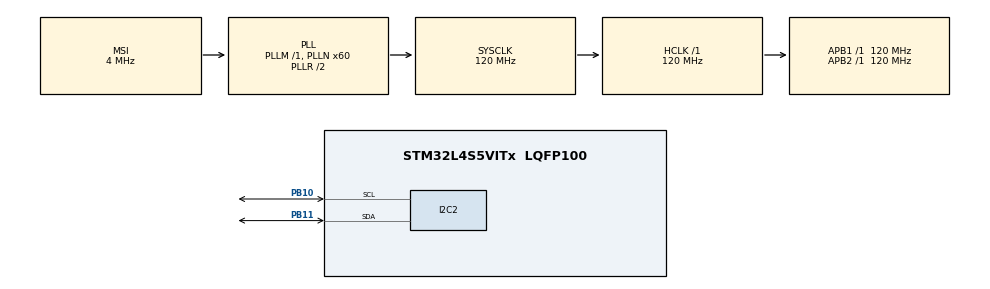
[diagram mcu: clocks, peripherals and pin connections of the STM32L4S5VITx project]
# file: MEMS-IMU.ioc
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I2C2.Timing=0x30A175AB
Mcu.Family=STM32L4
Mcu.Name=STM32L4S5VITx
Mcu.Package=LQFP100
NVIC.PriorityGroup=NVIC_PRIORITYGROUP_4
PB10.Mode=I2C
PB10.Signal=I2C2_SCL
PB11.Mode=I2C
PB11.Signal=I2C2_SDA
ProjectManager.HeapSize=0x200
ProjectManager.StackSize=0x400
ProjectManager.TargetToolchain=STM32CubeIDE
RCC.ADCFreq_Value=48000000
RCC.AHBFreq_Value=120000000
RCC.APB1Freq_Value=120000000
RCC.APB1TimFreq_Value=120000000
RCC.APB2Freq_Value=120000000
RCC.APB2TimFreq_Value=120000000
RCC.CortexFreq_Value=120000000
RCC.HCLKFreq_Value=120000000
RCC.HSE_VALUE=8000000
RCC.HSI48_VALUE=48000000
RCC.HSI_VALUE=16000000
RCC.MSI_VALUE=4000000
RCC.PLLN=60
RCC.PLLSAI1N=24
RCC.SYSCLKFreq_VALUE=120000000
RCC.SYSCLKSource=RCC_SYSCLKSOURCE_PLLCLK
RCC.USBFreq_Value=48000000
RCC.VCOOutputFreq_Value=240000000
board=B-L4S5I-IOT01A

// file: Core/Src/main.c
/* USER CODE BEGIN Header */
/**
  ******************************************************************************
  * @file           : main.c
  * @brief          : Main program body
  ******************************************************************************
  * @attention
  *
  * Copyright (c) 2026 STMicroelectronics.
  * All rights reserved.
  *
  * This software is licensed under terms that can be found in the LICENSE file
  * in the root directory of this software component.
  * If no LICENSE file comes with this software, it is provided AS-IS.
  *
  ******************************************************************************
  */
/* USER CODE END Header */
#include "main.h"

/* USER CODE BEGIN Includes */
#include "LSM6DSL.h"
#include <stdint.h>

HAL_StatusTypeDef status;

int16_t raw_x;
int16_t raw_y;
int16_t raw_z;

float ax_mg;
float ay_mg;
float az_mg;

float ax_g;
float ay_g;
float az_g;

float ax_ms2;
float ay_ms2;
float az_ms2;

int16_t gx, gy, gz;

float gx_dps;
float gy_dps;
float gz_dps;

/* USER CODE END Includes */

I2C_HandleTypeDef hi2c2;

void SystemClock_Config(void);
static void MX_GPIO_Init(void);
static void MX_I2C2_Init(void);
/* USER CODE BEGIN PFP */
int __io_putchar(int ch)
{
    ITM_SendChar(ch);
    return ch;
}
/* USER CODE END PFP */

int main(void)
{

  /* MCU Configuration--------------------------------------------------------*/

  /* Reset of all peripherals, Initializes the Flash interface and the Systick. */
  HAL_Init();

  /* Configure the system clock */
  SystemClock_Config();

  /* Initialize all configured peripherals */
  MX_GPIO_Init();
  MX_I2C2_Init();
  /* USER CODE BEGIN 2 */

  if (LSM6DSL_Init() != HAL_OK)
  {
      printf("LSM6DSL initialization FAILED\r\n");

      while (1)
      {
      }
  }

  printf("LSM6DSL initialization OK\r\n");

  /* USER CODE END 2 */

  /* Infinite loop */
  while (1)
  {

    /* USER CODE BEGIN 3 */
	  if (LSM6DSL_ReadAccel(&raw_x,
	                            &raw_y,
	                            &raw_z) == HAL_OK)
	      {
	          /*
	           * ±2 g sensitivity
	           *
	           * 0.061 mg/LSB
	           */

	          ax_mg = raw_x * 0.061f;
	          ay_mg = raw_y * 0.061f;
	          az_mg = raw_z * 0.061f;

	          /* Convert mg → g */

	          ax_g = ax_mg / 1000.0f;
	          ay_g = ay_mg / 1000.0f;
	          az_g = az_mg / 1000.0f;

	          /* Convert g → m/s² */

	          ax_ms2 = ax_g * 9.80665f;
	          ay_ms2 = ay_g * 9.80665f;
	          az_ms2 = az_g * 9.80665f;

	          printf("\r\n");

	          printf("RAW: ");
	          printf("X=%d  ", raw_x);
	          printf("Y=%d  ", raw_y);
	          printf("Z=%d\r\n", raw_z);

	          printf("ACC: ");
	          printf("X=%.3f mg  ", ax_mg);
	          printf("Y=%.3f mg  ", ay_mg);
	          printf("Z=%.3f mg\r\n", az_mg);

	          printf("ACC: ");
	          printf("X=%.3f g  ", ax_g);
	          printf("Y=%.3f g  ", ay_g);
	          printf("Z=%.3f g\r\n", az_g);

	          printf("ACC: ");
	          printf("X=%.3f m/s2  ", ax_ms2);
	          printf("Y=%.3f m/s2  ", ay_ms2);
	          printf("Z=%.3f m/s2\r\n", az_ms2);
	      }
	      else
	      {
	          printf("Accelerometer read error\r\n");
	      }

	      if(LSM6DSL_ReadGyro(&gx, &gy, &gz) == HAL_OK){

	      /* ±245 dps → 8.75 mdps/LSB = 0.00875 dps/LSB */

	      gx_dps = gx * 0.00875f;
	      gy_dps = gy * 0.00875f;
	      gz_dps = gz * 0.00875f;

	      printf("GX: %.2f dps | GY: %.2f dps | GZ: %.2f dps\r\n",
	             gx_dps,
	             gy_dps,
	             gz_dps);

	      }
	      else{
	          printf("Gyroscope read error\r\n");

	      }

	      HAL_Delay(100);

  }
  /* USER CODE END 3 */
}

void SystemClock_Config(void)
{
  RCC_OscInitTypeDef RCC_OscInitStruct = {0};
  RCC_ClkInitTypeDef RCC_ClkInitStruct = {0};

  /** Configure the main internal regulator output voltage
  */
  if (HAL_PWREx_ControlVoltageScaling(PWR_REGULATOR_VOLTAGE_SCALE1_BOOST) != HAL_OK)
  {
    Error_Handler();
  }

  /** Initializes the RCC Oscillators according to the specified parameters
  * in the RCC_OscInitTypeDef structure.
  */
  RCC_OscInitStruct.OscillatorType = RCC_OSCILLATORTYPE_MSI;
  RCC_OscInitStruct.MSIState = RCC_MSI_ON;
  RCC_OscInitStruct.MSICalibrationValue = 0;
  RCC_OscInitStruct.MSIClockRange = RCC_MSIRANGE_6;
  RCC_OscInitStruct.PLL.PLLState = RCC_PLL_ON;
  RCC_OscInitStruct.PLL.PLLSource = RCC_PLLSOURCE_MSI;
  RCC_OscInitStruct.PLL.PLLM = 1;
  RCC_OscInitStruct.PLL.PLLN = 60;
  RCC_OscInitStruct.PLL.PLLP = RCC_PLLP_DIV2;
  RCC_OscInitStruct.PLL.PLLQ = RCC_PLLQ_DIV2;
  RCC_OscInitStruct.PLL.PLLR = RCC_PLLR_DIV2;
  if (HAL_RCC_OscConfig(&RCC_OscInitStruct) != HAL_OK)
  {
    Error_Handler();
  }

  /** Initializes the CPU, AHB and APB buses clocks
  */
  RCC_ClkInitStruct.ClockType = RCC_CLOCKTYPE_HCLK|RCC_CLOCKTYPE_SYSCLK
                              |RCC_CLOCKTYPE_PCLK1|RCC_CLOCKTYPE_PCLK2;
  RCC_ClkInitStruct.SYSCLKSource = RCC_SYSCLKSOURCE_PLLCLK;
  RCC_ClkInitStruct.AHBCLKDivider = RCC_SYSCLK_DIV1;
  RCC_ClkInitStruct.APB1CLKDivider = RCC_HCLK_DIV1;
  RCC_ClkInitStruct.APB2CLKDivider = RCC_HCLK_DIV1;

  if (HAL_RCC_ClockConfig(&RCC_ClkInitStruct, FLASH_LATENCY_5) != HAL_OK)
  {
    Error_Handler();
  }
}

static void MX_I2C2_Init(void)
{

  hi2c2.Instance = I2C2;
  hi2c2.Init.Timing = 0x30A175AB;
  hi2c2.Init.OwnAddress1 = 0;
  hi2c2.Init.AddressingMode = I2C_ADDRESSINGMODE_7BIT;
  hi2c2.Init.DualAddressMode = I2C_DUALADDRESS_DISABLE;
  hi2c2.Init.OwnAddress2 = 0;
  hi2c2.Init.OwnAddress2Masks = I2C_OA2_NOMASK;
  hi2c2.Init.GeneralCallMode = I2C_GENERALCALL_DISABLE;
  hi2c2.Init.NoStretchMode = I2C_NOSTRETCH_DISABLE;
  if (HAL_I2C_Init(&hi2c2) != HAL_OK)
  {
    Error_Handler();
  }

  /** Configure Analogue filter
  */
  if (HAL_I2CEx_ConfigAnalogFilter(&hi2c2, I2C_ANALOGFILTER_ENABLE) != HAL_OK)
  {
    Error_Handler();
  }

  /** Configure Digital filter
  */
  if (HAL_I2CEx_ConfigDigitalFilter(&hi2c2, 0) != HAL_OK)
  {
    Error_Handler();
  }

}

static void MX_GPIO_Init(void)
{

  /* GPIO Ports Clock Enable */
  __HAL_RCC_GPIOB_CLK_ENABLE();

}

void Error_Handler(void)
{
  __disable_irq();
  while (1)
  {
  }
}
